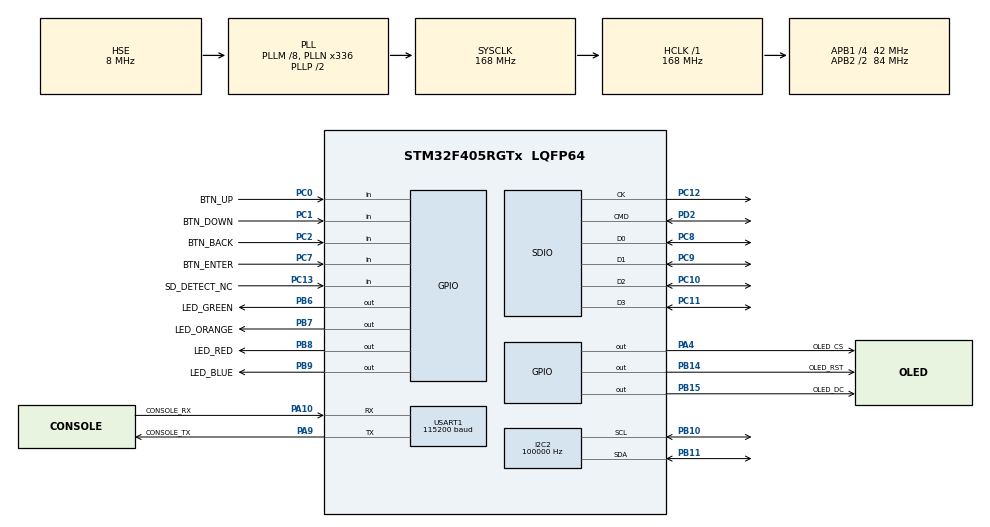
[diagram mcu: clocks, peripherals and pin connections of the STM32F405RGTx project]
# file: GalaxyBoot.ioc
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FATFS.BSP.number=1
FATFS._CODE_PAGE=437
FATFS._FS_READONLY=0
FATFS._MAX_LFN=255
FATFS._USE_FIND=1
FATFS._USE_LFN=1
FATFS0.BSP.STBoard=false
FATFS0.BSP.api=Unknown
FATFS0.BSP.instance=PC13-ANTI_TAMP
FATFS0.BSP.ip=GPIO
FATFS0.BSP.mode=Input
FATFS0.BSP.name=Detect_SDIO
FATFS0.BSP.solution=PC13-ANTI_TAMP
I2C2.ClockSpeed=100000
Mcu.Family=STM32F4
Mcu.Name=STM32F405RGTx
Mcu.Package=LQFP64
NVIC.PriorityGroup=NVIC_PRIORITYGROUP_4
NVIC.SDIO_IRQn=true\:1\:0\:false\:false\:true\:true\:true\:true
NVIC.USART1_IRQn=true\:2\:0\:false\:false\:true\:true\:true\:true
PA10.GPIO_Label=CONSOLE_RX
PA10.Mode=Asynchronous
PA10.Signal=USART1_RX
PA13.Mode=Serial_Wire
PA13.Signal=SYS_JTMS-SWDIO
PA14.Mode=Serial_Wire
PA14.Signal=SYS_JTCK-SWCLK
PA4.GPIO_Label=OLED_CS
PA4.GPIO_Speed=GPIO_SPEED_FREQ_HIGH
PA4.PinState=GPIO_PIN_SET
PA4.Signal=GPIO_Output
PA9.GPIO_Label=CONSOLE_TX
PA9.Mode=Asynchronous
PA9.Signal=USART1_TX
PB10.Mode=I2C
PB10.Signal=I2C2_SCL
PB11.Mode=I2C
PB11.Signal=I2C2_SDA
PB14.GPIO_Label=OLED_RST
PB14.PinState=GPIO_PIN_SET
PB14.Signal=GPIO_Output
PB15.GPIO_Label=OLED_DC
PB15.GPIO_Speed=GPIO_SPEED_FREQ_HIGH
PB15.Signal=GPIO_Output
PB6.GPIO_Label=LED_GREEN
PB6.Signal=GPIO_Output
PB7.GPIO_Label=LED_ORANGE
PB7.Signal=GPIO_Output
PB8.GPIO_Label=LED_RED
PB8.Signal=GPIO_Output
PB9.GPIO_Label=LED_BLUE
PB9.Signal=GPIO_Output
PC0.GPIO_Label=BTN_UP
PC0.GPIO_PuPd=GPIO_PULLDOWN
PC0.Signal=GPIO_Input
PC1.GPIO_Label=BTN_DOWN
PC1.GPIO_PuPd=GPIO_PULLDOWN
PC1.Signal=GPIO_Input
PC10.Mode=SD_4_bits_Wide_bus
PC10.Signal=SDIO_D2
PC11.Mode=SD_4_bits_Wide_bus
PC11.Signal=SDIO_D3
PC12.Mode=SD_4_bits_Wide_bus
PC12.Signal=SDIO_CK
PC13-ANTI_TAMP.GPIO_Label=SD_DETECT_NC
PC13-ANTI_TAMP.GPIO_PuPd=GPIO_PULLDOWN
PC13-ANTI_TAMP.Signal=GPIO_Input
PC2.GPIO_Label=BTN_BACK
PC2.GPIO_PuPd=GPIO_PULLDOWN
PC2.Signal=GPIO_Input
PC7.GPIO_Label=BTN_ENTER
PC7.GPIO_PuPd=GPIO_PULLDOWN
PC7.Signal=GPIO_Input
PC8.Mode=SD_4_bits_Wide_bus
PC8.Signal=SDIO_D0
PC9.Mode=SD_4_bits_Wide_bus
PC9.Signal=SDIO_D1
PD2.Mode=SD_4_bits_Wide_bus
PD2.Signal=SDIO_CMD
PH0-OSC_IN.Mode=HSE-External-Oscillator
PH0-OSC_IN.Signal=RCC_OSC_IN
PH1-OSC_OUT.Mode=HSE-External-Oscillator
PH1-OSC_OUT.Signal=RCC_OSC_OUT
ProjectManager.HeapSize=0x400
ProjectManager.StackSize=0x800
ProjectManager.TargetToolchain=CMake
RCC.AHBFreq_Value=168000000
RCC.APB1CLKDivider=RCC_HCLK_DIV4
RCC.APB1Freq_Value=42000000
RCC.APB1TimFreq_Value=84000000
RCC.APB2CLKDivider=RCC_HCLK_DIV2
RCC.APB2Freq_Value=84000000
RCC.APB2TimFreq_Value=168000000
RCC.CortexFreq_Value=168000000
RCC.HCLKFreq_Value=168000000
RCC.HSE_VALUE=8000000
RCC.HSI_VALUE=16000000
RCC.LSE_VALUE=32768
RCC.PLLM=8
RCC.PLLN=336
RCC.PLLQ=7
RCC.PLLSourceVirtual=RCC_PLLSOURCE_HSE
RCC.SYSCLKFreq_VALUE=168000000
RCC.SYSCLKSource=RCC_SYSCLKSOURCE_PLLCLK
RCC.VCOOutputFreq_Value=336000000
SDIO.ClockDiv=4
SDIO.WideMode=SDIO_BUS_WIDE_4B
USART1.BaudRate=115200
USART1.VirtualMode=VM_ASYNC
VP_FATFS_VS_SDIO.Mode=SDIO
board=custom

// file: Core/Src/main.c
/* USER CODE BEGIN Header */
/**
  ******************************************************************************
  * @file           : main.c
  * @brief          : Main program body
  ******************************************************************************
  * @attention
  *
  * Copyright (c) 2026 STMicroelectronics.
  * All rights reserved.
  *
  * This software is licensed under terms that can be found in the LICENSE file
  * in the root directory of this software component.
  * If no LICENSE file comes with this software, it is provided AS-IS.
  *
  ******************************************************************************
  */
/* USER CODE END Header */
#include "main.h"
#include "fatfs.h"
#include "i2c.h"
#include "sdio.h"
#include "usart.h"
#include "gpio.h"

/* USER CODE BEGIN Includes */
#include "boot_main.h"
/* USER CODE END Includes */

void SystemClock_Config(void);

int main(void)
{

  /* MCU Configuration--------------------------------------------------------*/

  /* Reset of all peripherals, Initializes the Flash interface and the Systick. */
  HAL_Init();

  /* Configure the system clock */
  SystemClock_Config();

  /* Initialize all configured peripherals */
  MX_GPIO_Init();
  MX_I2C2_Init();
  MX_SDIO_SD_Init();
  MX_USART1_UART_Init();
  MX_FATFS_Init();
  /* USER CODE BEGIN 2 */
  Boot_Main();   /* starts the application or updates it; does not return */

  /* USER CODE END 2 */

  /* Infinite loop */
  while (1)
  {

  }
}

void SystemClock_Config(void)
{
  RCC_OscInitTypeDef RCC_OscInitStruct = {0};
  RCC_ClkInitTypeDef RCC_ClkInitStruct = {0};

  /** Configure the main internal regulator output voltage
  */
  __HAL_RCC_PWR_CLK_ENABLE();
  __HAL_PWR_VOLTAGESCALING_CONFIG(PWR_REGULATOR_VOLTAGE_SCALE1);

  /** Initializes the RCC Oscillators according to the specified parameters
  * in the RCC_OscInitTypeDef structure.
  */
  RCC_OscInitStruct.OscillatorType = RCC_OSCILLATORTYPE_HSE;
  RCC_OscInitStruct.HSEState = RCC_HSE_ON;
  RCC_OscInitStruct.PLL.PLLState = RCC_PLL_ON;
  RCC_OscInitStruct.PLL.PLLSource = RCC_PLLSOURCE_HSE;
  RCC_OscInitStruct.PLL.PLLM = 8;
  RCC_OscInitStruct.PLL.PLLN = 336;
  RCC_OscInitStruct.PLL.PLLP = RCC_PLLP_DIV2;
  RCC_OscInitStruct.PLL.PLLQ = 7;
  if (HAL_RCC_OscConfig(&RCC_OscInitStruct) != HAL_OK)
  {
    Error_Handler();
  }

  /** Initializes the CPU, AHB and APB buses clocks
  */
  RCC_ClkInitStruct.ClockType = RCC_CLOCKTYPE_HCLK|RCC_CLOCKTYPE_SYSCLK
                              |RCC_CLOCKTYPE_PCLK1|RCC_CLOCKTYPE_PCLK2;
  RCC_ClkInitStruct.SYSCLKSource = RCC_SYSCLKSOURCE_PLLCLK;
  RCC_ClkInitStruct.AHBCLKDivider = RCC_SYSCLK_DIV1;
  RCC_ClkInitStruct.APB1CLKDivider = RCC_HCLK_DIV4;
  RCC_ClkInitStruct.APB2CLKDivider = RCC_HCLK_DIV2;

  if (HAL_RCC_ClockConfig(&RCC_ClkInitStruct, FLASH_LATENCY_5) != HAL_OK)
  {
    Error_Handler();
  }
}

void Error_Handler(void)
{
  __disable_irq();
  while (1)
  {
  }
}
